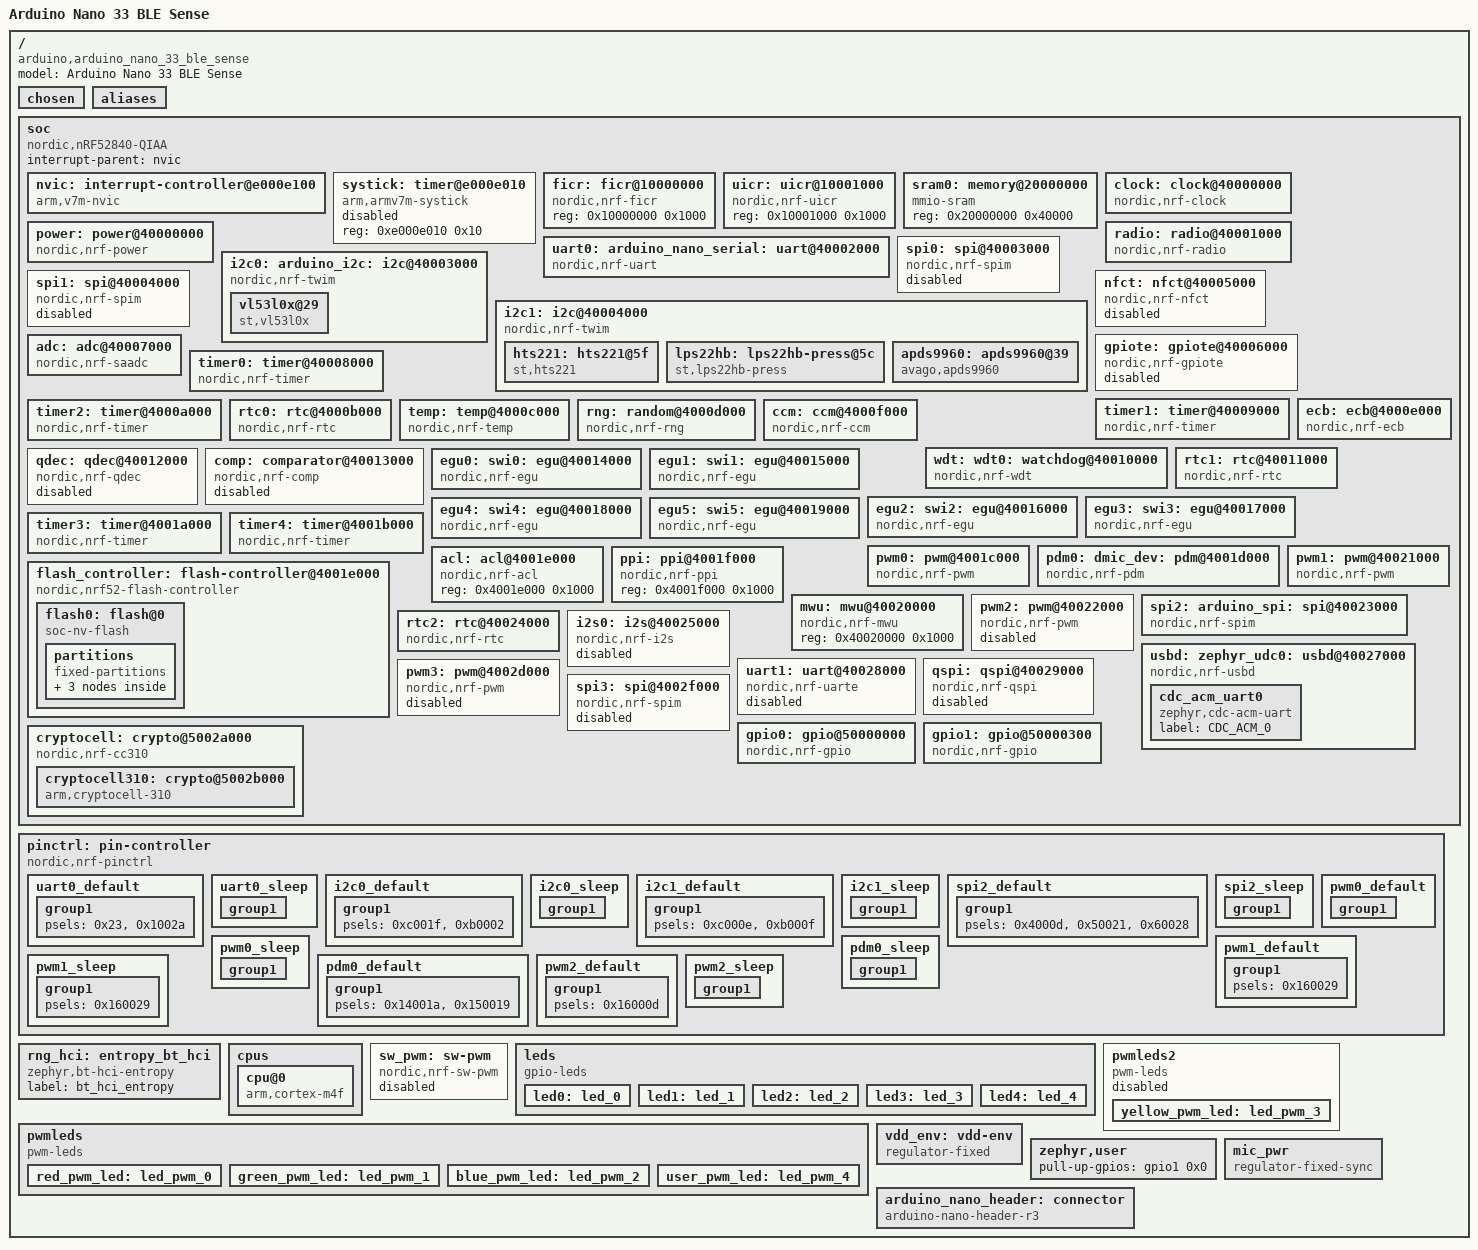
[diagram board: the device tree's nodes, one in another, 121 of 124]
/dts-v1/;

/ {
	#address-cells = < 0x1 >;
	#size-cells = < 0x1 >;
	model = "Arduino Nano 33 BLE Sense";
	compatible = "arduino,arduino_nano_33_ble_sense";
	chosen {
		zephyr,entropy = &rng;
		zephyr,flash-controller = &flash_controller;
		zephyr,console = &cdc_acm_uart0;
		zephyr,shell-uart = &uart0;
		zephyr,uart-mcumgr = &uart0;
		zephyr,bt-mon-uart = &uart0;
		zephyr,bt-c2h-uart = &uart0;
		zephyr,sram = &sram0;
		zephyr,flash = &flash0;
		zephyr,code-partition = &code_partition;
	};
	aliases {
		led0 = &led0;
		led1 = &led1;
		led2 = &led2;
		led3 = &led3;
		led4 = &led4;
		pwm-led0 = &red_pwm_led;
		pwm-led1 = &green_pwm_led;
		pwm-led2 = &blue_pwm_led;
		pwm-led3 = &yellow_pwm_led;
		pwm-led4 = &user_pwm_led;
		red-pwm-led = &red_pwm_led;
		green-pwm-led = &green_pwm_led;
		blue-pwm-led = &blue_pwm_led;
		spi = &spi2;
	};
	soc {
		#address-cells = < 0x1 >;
		#size-cells = < 0x1 >;
		compatible = "nordic,nRF52840-QIAA", "nordic,nRF52840", "nordic,nRF52", "simple-bus";
		interrupt-parent = < &nvic >;
		ranges;
		nvic: interrupt-controller@e000e100 {
			#address-cells = < 0x1 >;
			compatible = "arm,v7m-nvic";
			reg = < 0xe000e100 0xc00 >;
			interrupt-controller;
			#interrupt-cells = < 0x2 >;
			arm,num-irq-priority-bits = < 0x3 >;
			phandle = < 0x1 >;
		};
		systick: timer@e000e010 {
			compatible = "arm,armv7m-systick";
			reg = < 0xe000e010 0x10 >;
			status = "disabled";
		};
		ficr: ficr@10000000 {
			compatible = "nordic,nrf-ficr";
			reg = < 0x10000000 0x1000 >;
			status = "okay";
		};
		uicr: uicr@10001000 {
			compatible = "nordic,nrf-uicr";
			reg = < 0x10001000 0x1000 >;
			status = "okay";
		};
		sram0: memory@20000000 {
			compatible = "mmio-sram";
			reg = < 0x20000000 0x40000 >;
		};
		clock: clock@40000000 {
			compatible = "nordic,nrf-clock";
			reg = < 0x40000000 0x1000 >;
			interrupts = < 0x0 0x1 >;
			status = "okay";
			label = "CLOCK";
		};
		power: power@40000000 {
			compatible = "nordic,nrf-power";
			reg = < 0x40000000 0x1000 >;
			interrupts = < 0x0 0x1 >;
			status = "okay";
		};
		radio: radio@40001000 {
			compatible = "nordic,nrf-radio";
			reg = < 0x40001000 0x1000 >;
			interrupts = < 0x1 0x1 >;
			status = "okay";
			ieee802154-supported;
			ble-2mbps-supported;
			ble-coded-phy-supported;
			tx-high-power-supported;
		};
		uart0: arduino_nano_serial: uart@40002000 {
			compatible = "nordic,nrf-uart";
			reg = < 0x40002000 0x1000 >;
			interrupts = < 0x2 0x1 >;
			status = "okay";
			label = "UART_0";
			current-speed = < 0x1c200 >;
			pinctrl-0 = < &uart0_default >;
			pinctrl-1 = < &uart0_sleep >;
			pinctrl-names = "default", "sleep";
		};
		i2c0: arduino_i2c: arduino_nano_i2c: i2c@40003000 {
			compatible = "nordic,nrf-twim";
			#address-cells = < 0x1 >;
			#size-cells = < 0x0 >;
			reg = < 0x40003000 0x1000 >;
			clock-frequency = < 0x186a0 >;
			interrupts = < 0x3 0x1 >;
			status = "okay";
			label = "I2C_0";
			pinctrl-0 = < &i2c0_default >;
			pinctrl-1 = < &i2c0_sleep >;
			pinctrl-names = "default", "sleep";
			vl53l0x@29 {
				compatible = "st,vl53l0x";
				reg = < 0x29 >;
				label = "VL53L0X";
			};
		};
		spi0: spi@40003000 {
			compatible = "nordic,nrf-spim";
			#address-cells = < 0x1 >;
			#size-cells = < 0x0 >;
			reg = < 0x40003000 0x1000 >;
			interrupts = < 0x3 0x1 >;
			status = "disabled";
			label = "SPI_0";
		};
		i2c1: i2c@40004000 {
			compatible = "nordic,nrf-twim";
			#address-cells = < 0x1 >;
			#size-cells = < 0x0 >;
			reg = < 0x40004000 0x1000 >;
			clock-frequency = < 0x186a0 >;
			interrupts = < 0x4 0x1 >;
			status = "okay";
			label = "I2C_1";
			pinctrl-0 = < &i2c1_default >;
			pinctrl-1 = < &i2c1_sleep >;
			pinctrl-names = "default", "sleep";
			hts221: hts221@5f {
				compatible = "st,hts221";
				status = "okay";
				reg = < 0x5f >;
				label = "HTS221";
			};
			lps22hb: lps22hb-press@5c {
				compatible = "st,lps22hb-press";
				status = "okay";
				reg = < 0x5c >;
				label = "LPS22HB";
			};
			apds9960: apds9960@39 {
				compatible = "avago,apds9960";
				status = "okay";
				reg = < 0x39 >;
				label = "APDS9960";
				int-gpios = < &gpio0 0x13 0x11 >;
			};
		};
		spi1: spi@40004000 {
			compatible = "nordic,nrf-spim";
			#address-cells = < 0x1 >;
			#size-cells = < 0x0 >;
			reg = < 0x40004000 0x1000 >;
			interrupts = < 0x4 0x1 >;
			status = "disabled";
			label = "SPI_1";
		};
		nfct: nfct@40005000 {
			compatible = "nordic,nrf-nfct";
			reg = < 0x40005000 0x1000 >;
			interrupts = < 0x5 0x1 >;
			status = "disabled";
		};
		gpiote: gpiote@40006000 {
			compatible = "nordic,nrf-gpiote";
			reg = < 0x40006000 0x1000 >;
			interrupts = < 0x6 0x5 >;
			status = "disabled";
			label = "GPIOTE_0";
		};
		adc: adc@40007000 {
			compatible = "nordic,nrf-saadc";
			reg = < 0x40007000 0x1000 >;
			interrupts = < 0x7 0x1 >;
			status = "okay";
			label = "ADC_0";
			#io-channel-cells = < 0x1 >;
		};
		timer0: timer@40008000 {
			compatible = "nordic,nrf-timer";
			status = "okay";
			reg = < 0x40008000 0x1000 >;
			cc-num = < 0x4 >;
			interrupts = < 0x8 0x1 >;
			prescaler = < 0x0 >;
			label = "TIMER_0";
		};
		timer1: timer@40009000 {
			compatible = "nordic,nrf-timer";
			status = "okay";
			reg = < 0x40009000 0x1000 >;
			cc-num = < 0x4 >;
			interrupts = < 0x9 0x1 >;
			prescaler = < 0x0 >;
			label = "TIMER_1";
		};
		timer2: timer@4000a000 {
			compatible = "nordic,nrf-timer";
			status = "okay";
			reg = < 0x4000a000 0x1000 >;
			cc-num = < 0x4 >;
			interrupts = < 0xa 0x1 >;
			prescaler = < 0x0 >;
			label = "TIMER_2";
			phandle = < 0x13 >;
		};
		rtc0: rtc@4000b000 {
			compatible = "nordic,nrf-rtc";
			reg = < 0x4000b000 0x1000 >;
			cc-num = < 0x3 >;
			interrupts = < 0xb 0x1 >;
			status = "okay";
			clock-frequency = < 0x8000 >;
			prescaler = < 0x1 >;
			label = "RTC_0";
		};
		temp: temp@4000c000 {
			compatible = "nordic,nrf-temp";
			reg = < 0x4000c000 0x1000 >;
			interrupts = < 0xc 0x1 >;
			status = "okay";
			label = "TEMP_0";
		};
		rng: random@4000d000 {
			compatible = "nordic,nrf-rng";
			reg = < 0x4000d000 0x1000 >;
			interrupts = < 0xd 0x1 >;
			status = "okay";
			label = "RNG";
		};
		ecb: ecb@4000e000 {
			compatible = "nordic,nrf-ecb";
			reg = < 0x4000e000 0x1000 >;
			interrupts = < 0xe 0x1 >;
			status = "okay";
			label = "ECB";
		};
		ccm: ccm@4000f000 {
			compatible = "nordic,nrf-ccm";
			reg = < 0x4000f000 0x1000 >;
			interrupts = < 0xf 0x1 >;
			length-field-length-8-bits;
			status = "okay";
		};
		wdt: wdt0: watchdog@40010000 {
			compatible = "nordic,nrf-wdt";
			reg = < 0x40010000 0x1000 >;
			interrupts = < 0x10 0x1 >;
			status = "okay";
			label = "WDT";
		};
		rtc1: rtc@40011000 {
			compatible = "nordic,nrf-rtc";
			reg = < 0x40011000 0x1000 >;
			cc-num = < 0x4 >;
			interrupts = < 0x11 0x1 >;
			status = "okay";
			clock-frequency = < 0x8000 >;
			prescaler = < 0x1 >;
			label = "RTC_1";
		};
		qdec: qdec@40012000 {
			compatible = "nordic,nrf-qdec";
			reg = < 0x40012000 0x1000 >;
			interrupts = < 0x12 0x1 >;
			status = "disabled";
			label = "QDEC";
		};
		comp: comparator@40013000 {
			compatible = "nordic,nrf-comp";
			reg = < 0x40013000 0x1000 >;
			interrupts = < 0x13 0x1 >;
			status = "disabled";
			#io-channel-cells = < 0x1 >;
		};
		egu0: swi0: egu@40014000 {
			compatible = "nordic,nrf-egu", "nordic,nrf-swi";
			reg = < 0x40014000 0x1000 >;
			interrupts = < 0x14 0x1 >;
			status = "okay";
		};
		egu1: swi1: egu@40015000 {
			compatible = "nordic,nrf-egu", "nordic,nrf-swi";
			reg = < 0x40015000 0x1000 >;
			interrupts = < 0x15 0x1 >;
			status = "okay";
		};
		egu2: swi2: egu@40016000 {
			compatible = "nordic,nrf-egu", "nordic,nrf-swi";
			reg = < 0x40016000 0x1000 >;
			interrupts = < 0x16 0x1 >;
			status = "okay";
		};
		egu3: swi3: egu@40017000 {
			compatible = "nordic,nrf-egu", "nordic,nrf-swi";
			reg = < 0x40017000 0x1000 >;
			interrupts = < 0x17 0x1 >;
			status = "okay";
		};
		egu4: swi4: egu@40018000 {
			compatible = "nordic,nrf-egu", "nordic,nrf-swi";
			reg = < 0x40018000 0x1000 >;
			interrupts = < 0x18 0x1 >;
			status = "okay";
		};
		egu5: swi5: egu@40019000 {
			compatible = "nordic,nrf-egu", "nordic,nrf-swi";
			reg = < 0x40019000 0x1000 >;
			interrupts = < 0x19 0x1 >;
			status = "okay";
		};
		timer3: timer@4001a000 {
			compatible = "nordic,nrf-timer";
			status = "okay";
			reg = < 0x4001a000 0x1000 >;
			cc-num = < 0x6 >;
			interrupts = < 0x1a 0x1 >;
			prescaler = < 0x0 >;
			label = "TIMER_3";
		};
		timer4: timer@4001b000 {
			compatible = "nordic,nrf-timer";
			status = "okay";
			reg = < 0x4001b000 0x1000 >;
			cc-num = < 0x6 >;
			interrupts = < 0x1b 0x1 >;
			prescaler = < 0x0 >;
			label = "TIMER_4";
		};
		pwm0: pwm@4001c000 {
			compatible = "nordic,nrf-pwm";
			reg = < 0x4001c000 0x1000 >;
			interrupts = < 0x1c 0x1 >;
			status = "okay";
			label = "PWM_0";
			#pwm-cells = < 0x3 >;
			pinctrl-0 = < &pwm0_default >;
			pinctrl-1 = < &pwm0_sleep >;
			pinctrl-names = "default", "sleep";
			phandle = < 0x15 >;
		};
		pdm0: dmic_dev: pdm@4001d000 {
			compatible = "nordic,nrf-pdm";
			reg = < 0x4001d000 0x1000 >;
			interrupts = < 0x1d 0x1 >;
			status = "okay";
			label = "PDM_0";
			pinctrl-0 = < &pdm0_default >;
			pinctrl-1 = < &pdm0_sleep >;
			pinctrl-names = "default", "sleep";
			clock-source = "PCLK32M_HFXO";
		};
		acl: acl@4001e000 {
			compatible = "nordic,nrf-acl";
			reg = < 0x4001e000 0x1000 >;
			status = "okay";
		};
		flash_controller: flash-controller@4001e000 {
			compatible = "nordic,nrf52-flash-controller";
			reg = < 0x4001e000 0x1000 >;
			partial-erase;
			#address-cells = < 0x1 >;
			#size-cells = < 0x1 >;
			label = "NRF_FLASH_DRV_NAME";
			flash0: flash@0 {
				compatible = "soc-nv-flash";
				label = "NRF_FLASH";
				erase-block-size = < 0x1000 >;
				write-block-size = < 0x4 >;
				reg = < 0x0 0x100000 >;
				partitions {
					compatible = "fixed-partitions";
					#address-cells = < 0x1 >;
					#size-cells = < 0x1 >;
					boot_partition: partition@0 {
						label = "sam-ba";
						reg = < 0x0 0x10000 >;
						read-only;
					};
					code_partition: partition@10000 {
						label = "code";
						reg = < 0x10000 0xe8000 >;
						read-only;
					};
					storage_partition: partition@f8000 {
						label = "storage";
						reg = < 0xf8000 0x8000 >;
					};
				};
			};
		};
		ppi: ppi@4001f000 {
			compatible = "nordic,nrf-ppi";
			reg = < 0x4001f000 0x1000 >;
			status = "okay";
		};
		mwu: mwu@40020000 {
			compatible = "nordic,nrf-mwu";
			reg = < 0x40020000 0x1000 >;
			status = "okay";
		};
		pwm1: pwm@40021000 {
			compatible = "nordic,nrf-pwm";
			reg = < 0x40021000 0x1000 >;
			interrupts = < 0x21 0x1 >;
			status = "okay";
			label = "PWM_1";
			#pwm-cells = < 0x3 >;
			pinctrl-0 = < &pwm1_default >;
			pinctrl-1 = < &pwm1_sleep >;
			pinctrl-names = "default", "sleep";
			phandle = < 0x16 >;
		};
		pwm2: pwm@40022000 {
			compatible = "nordic,nrf-pwm";
			reg = < 0x40022000 0x1000 >;
			interrupts = < 0x22 0x1 >;
			status = "disabled";
			label = "PWM_2";
			#pwm-cells = < 0x3 >;
			pinctrl-0 = < &pwm2_default >;
			pinctrl-1 = < &pwm2_sleep >;
			pinctrl-names = "default", "sleep";
			phandle = < 0x17 >;
		};
		spi2: arduino_spi: arduino_nano_spi: spi@40023000 {
			compatible = "nordic,nrf-spim";
			#address-cells = < 0x1 >;
			#size-cells = < 0x0 >;
			reg = < 0x40023000 0x1000 >;
			interrupts = < 0x23 0x1 >;
			status = "okay";
			label = "SPI_2";
			pinctrl-0 = < &spi2_default >;
			pinctrl-1 = < &spi2_sleep >;
			pinctrl-names = "default", "sleep";
		};
		rtc2: rtc@40024000 {
			compatible = "nordic,nrf-rtc";
			reg = < 0x40024000 0x1000 >;
			cc-num = < 0x4 >;
			interrupts = < 0x24 0x1 >;
			status = "okay";
			clock-frequency = < 0x8000 >;
			prescaler = < 0x1 >;
			label = "RTC_2";
		};
		i2s0: i2s@40025000 {
			compatible = "nordic,nrf-i2s";
			#address-cells = < 0x1 >;
			#size-cells = < 0x0 >;
			reg = < 0x40025000 0x1000 >;
			interrupts = < 0x25 0x1 >;
			status = "disabled";
			label = "I2S_0";
		};
		usbd: zephyr_udc0: usbd@40027000 {
			compatible = "nordic,nrf-usbd";
			reg = < 0x40027000 0x1000 >;
			interrupts = < 0x27 0x1 >;
			num-bidir-endpoints = < 0x1 >;
			num-in-endpoints = < 0x7 >;
			num-out-endpoints = < 0x7 >;
			num-isoin-endpoints = < 0x1 >;
			num-isoout-endpoints = < 0x1 >;
			status = "okay";
			label = "USBD";
			cdc_acm_uart0: cdc_acm_uart0 {
				compatible = "zephyr,cdc-acm-uart";
				label = "CDC_ACM_0";
			};
		};
		uart1: uart@40028000 {
			compatible = "nordic,nrf-uarte";
			reg = < 0x40028000 0x1000 >;
			interrupts = < 0x28 0x1 >;
			status = "disabled";
			label = "UART_1";
		};
		qspi: qspi@40029000 {
			compatible = "nordic,nrf-qspi";
			#address-cells = < 0x1 >;
			#size-cells = < 0x0 >;
			reg = < 0x40029000 0x1000 >, < 0x12000000 0x8000000 >;
			reg-names = "qspi", "qspi_mm";
			interrupts = < 0x29 0x1 >;
			status = "disabled";
			label = "QSPI";
		};
		pwm3: pwm@4002d000 {
			compatible = "nordic,nrf-pwm";
			reg = < 0x4002d000 0x1000 >;
			interrupts = < 0x2d 0x1 >;
			status = "disabled";
			label = "PWM_3";
			#pwm-cells = < 0x3 >;
		};
		spi3: spi@4002f000 {
			compatible = "nordic,nrf-spim";
			#address-cells = < 0x1 >;
			#size-cells = < 0x0 >;
			reg = < 0x4002f000 0x1000 >;
			interrupts = < 0x2f 0x1 >;
			status = "disabled";
			label = "SPI_3";
		};
		gpio0: gpio@50000000 {
			compatible = "nordic,nrf-gpio";
			gpio-controller;
			reg = < 0x50000000 0x200 0x50000500 0x300 >;
			#gpio-cells = < 0x2 >;
			label = "GPIO_0";
			status = "okay";
			port = < 0x0 >;
			phandle = < 0x8 >;
		};
		gpio1: gpio@50000300 {
			compatible = "nordic,nrf-gpio";
			gpio-controller;
			reg = < 0x50000300 0x200 0x50000800 0x300 >;
			#gpio-cells = < 0x2 >;
			ngpios = < 0x10 >;
			label = "GPIO_1";
			status = "okay";
			port = < 0x1 >;
			phandle = < 0x14 >;
		};
		cryptocell: crypto@5002a000 {
			compatible = "nordic,nrf-cc310";
			reg = < 0x5002a000 0x1000 >;
			label = "CRYPTOCELL";
			status = "okay";
			#address-cells = < 0x1 >;
			#size-cells = < 0x1 >;
			cryptocell310: crypto@5002b000 {
				compatible = "arm,cryptocell-310";
				reg = < 0x5002b000 0x1000 >;
				interrupts = < 0x2a 0x1 >;
				label = "CRYPTOCELL310";
			};
		};
	};
	pinctrl: pin-controller {
		compatible = "nordic,nrf-pinctrl";
		uart0_default: uart0_default {
			phandle = < 0x2 >;
			group1 {
				psels = < 0x23 >, < 0x1002a >;
			};
		};
		uart0_sleep: uart0_sleep {
			phandle = < 0x3 >;
			group1 {
				psels = < 0x23 >, < 0x1002a >;
				low-power-enable;
			};
		};
		i2c0_default: i2c0_default {
			phandle = < 0x4 >;
			group1 {
				psels = < 0xc001f >, < 0xb0002 >;
			};
		};
		i2c0_sleep: i2c0_sleep {
			phandle = < 0x5 >;
			group1 {
				psels = < 0xc001f >, < 0xb0002 >;
				low-power-enable;
			};
		};
		i2c1_default: i2c1_default {
			phandle = < 0x6 >;
			group1 {
				psels = < 0xc000e >, < 0xb000f >;
			};
		};
		i2c1_sleep: i2c1_sleep {
			phandle = < 0x7 >;
			group1 {
				psels = < 0xc000e >, < 0xb000f >;
				low-power-enable;
			};
		};
		spi2_default: spi2_default {
			phandle = < 0x11 >;
			group1 {
				psels = < 0x4000d >, < 0x50021 >, < 0x60028 >;
			};
		};
		spi2_sleep: spi2_sleep {
			phandle = < 0x12 >;
			group1 {
				psels = < 0x4000d >, < 0x50021 >, < 0x60028 >;
				low-power-enable;
			};
		};
		pwm0_default: pwm0_default {
			phandle = < 0x9 >;
			group1 {
				psels = < 0x160018 >, < 0x170010 >, < 0x180006 >;
				nordic,invert;
			};
		};
		pwm0_sleep: pwm0_sleep {
			phandle = < 0xa >;
			group1 {
				psels = < 0x160018 >, < 0x170010 >, < 0x180006 >;
				low-power-enable;
			};
		};
		pwm1_default: pwm1_default {
			phandle = < 0xd >;
			group1 {
				psels = < 0x160029 >;
			};
		};
		pwm1_sleep: pwm1_sleep {
			phandle = < 0xe >;
			group1 {
				psels = < 0x160029 >;
			};
		};
		pdm0_default: pdm0_default {
			phandle = < 0xb >;
			group1 {
				psels = < 0x14001a >, < 0x150019 >;
			};
		};
		pdm0_sleep: pdm0_sleep {
			phandle = < 0xc >;
			group1 {
				psels = < 0x14001a >, < 0x150019 >;
				low-power-enable;
			};
		};
		pwm2_default: pwm2_default {
			phandle = < 0xf >;
			group1 {
				psels = < 0x16000d >;
			};
		};
		pwm2_sleep: pwm2_sleep {
			phandle = < 0x10 >;
			group1 {
				psels = < 0x16000d >;
				low-power-enable;
			};
		};
	};
	rng_hci: entropy_bt_hci {
		compatible = "zephyr,bt-hci-entropy";
		label = "bt_hci_entropy";
		status = "okay";
	};
	cpus {
		#address-cells = < 0x1 >;
		#size-cells = < 0x0 >;
		cpu@0 {
			device_type = "cpu";
			compatible = "arm,cortex-m4f";
			reg = < 0x0 >;
			swo-ref-frequency = < 0x1e84800 >;
		};
	};
	sw_pwm: sw-pwm {
		compatible = "nordic,nrf-sw-pwm";
		status = "disabled";
		label = "SW_PWM";
		generator = < &timer2 >;
		clock-prescaler = < 0x0 >;
		#pwm-cells = < 0x3 >;
	};
	leds {
		compatible = "gpio-leds";
		led0: led_0 {
			gpios = < &gpio0 0x18 0x1 >;
			label = "Red LED";
		};
		led1: led_1 {
			gpios = < &gpio0 0x10 0x1 >;
			label = "Green LED";
		};
		led2: led_2 {
			gpios = < &gpio0 0x6 0x1 >;
			label = "Blue LED";
		};
		led3: led_3 {
			gpios = < &gpio0 0xd 0x0 >;
			label = "Yellow LED";
		};
		led4: led_4 {
			gpios = < &gpio1 0x9 0x0 >;
			label = "User LED";
		};
	};
	pwmleds {
		compatible = "pwm-leds";
		red_pwm_led: led_pwm_0 {
			pwms = < &pwm0 0x0 0x1312d00 0x1 >;
			label = "Red PWM LED";
		};
		green_pwm_led: led_pwm_1 {
			pwms = < &pwm0 0x1 0x1312d00 0x1 >;
			label = "Green PWM LED";
		};
		blue_pwm_led: led_pwm_2 {
			pwms = < &pwm0 0x2 0x1312d00 0x1 >;
			label = "Blue PWM LED";
		};
		user_pwm_led: led_pwm_4 {
			pwms = < &pwm1 0x0 0x1312d00 0x0 >;
			label = "User PWM LED";
		};
	};
	pwmleds2 {
		compatible = "pwm-leds";
		status = "disabled";
		yellow_pwm_led: led_pwm_3 {
			pwms = < &pwm2 0x0 0x1312d00 0x0 >;
			label = "Yellow PWM LED";
		};
	};
	vdd_env: vdd-env {
		compatible = "regulator-fixed";
		label = "vdd_env";
		regulator-name = "vdd_env";
		enable-gpios = < &gpio0 0x16 0x0 >;
		regulator-boot-on;
		startup-delay-us = < 0x1388 >;
	};
	zephyr,user {
		pull-up-gpios = < &gpio1 0x0 0x0 >;
	};
	arduino_nano_header: connector {
		compatible = "arduino-nano-header-r3";
		#gpio-cells = < 0x2 >;
		gpio-map-mask = < 0xffffffff 0xffffffc0 >;
		gpio-map-pass-thru = < 0x0 0x3f >;
		gpio-map = < 0x0 0x0 &gpio1 0x3 0x0 >, < 0x1 0x0 &gpio1 0xa 0x0 >, < 0x2 0x0 &gpio1 0xb 0x0 >, < 0x3 0x0 &gpio1 0xc 0x0 >, < 0x4 0x0 &gpio1 0xf 0x0 >, < 0x5 0x0 &gpio1 0xd 0x0 >, < 0x6 0x0 &gpio1 0xe 0x0 >, < 0x7 0x0 &gpio0 0x9 0x0 >, < 0x8 0x0 &gpio0 0xa 0x0 >, < 0x9 0x0 &gpio0 0x1b 0x0 >, < 0xa 0x0 &gpio1 0x2 0x0 >, < 0xb 0x0 &gpio1 0x1 0x0 >, < 0xc 0x0 &gpio1 0x8 0x0 >, < 0xd 0x0 &gpio0 0xd 0x0 >, < 0xe 0x0 &gpio0 0x4 0x0 >, < 0xf 0x0 &gpio0 0x5 0x0 >, < 0x10 0x0 &gpio0 0x1e 0x0 >, < 0x11 0x0 &gpio0 0x1d 0x0 >, < 0x12 0x0 &gpio0 0xe 0x0 >, < 0x13 0x0 &gpio0 0xf 0x0 >, < 0x14 0x0 &gpio0 0x1c 0x0 >, < 0x15 0x0 &gpio1 0x3 0x0 >;
	};
	mic_pwr: mic_pwr {
		compatible = "regulator-fixed-sync", "regulator-fixed";
		label = "mic_pwr";
		regulator-name = "mic_pwr";
		enable-gpios = < &gpio0 0x11 0x0 >;
		regulator-boot-on;
	};
};
